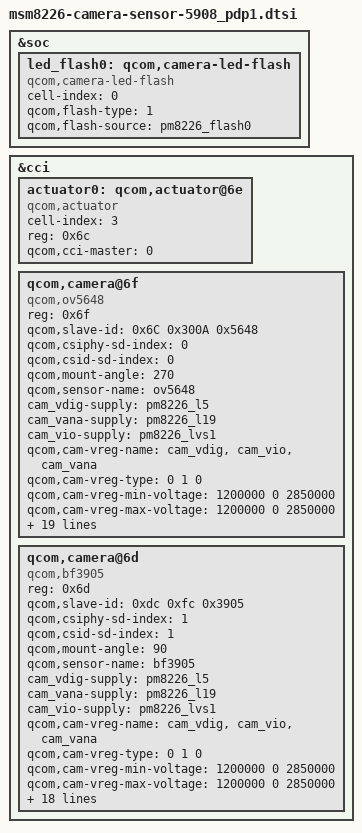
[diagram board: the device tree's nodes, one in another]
/*
 * Copyright (c) 2013, The Linux Foundation. All rights reserved.
 *
 * This program is free software; you can redistribute it and/or modify
 * it under the terms of the GNU General Public License version 2 and
 * only version 2 as published by the Free Software Foundation.
 *
 * This program is distributed in the hope that it will be useful,
 * but WITHOUT ANY WARRANTY; without even the implied warranty of
 * MERCHANTABILITY or FITNESS FOR A PARTICULAR PURPOSE.  See the
 * GNU General Public License for more details.
 */

&soc {

	led_flash0: qcom,camera-led-flash {
		cell-index = <0>;
		compatible = "qcom,camera-led-flash";
		qcom,flash-type = <1>;
		qcom,flash-source = <&pm8226_flash0>;
	};
};

&cci {

	actuator0: qcom,actuator@6e {
		cell-index = <3>;
		reg = <0x6c>;
		compatible = "qcom,actuator";
		qcom,cci-master = <0>;
	};

	qcom,camera@6f {
		compatible = "qcom,ov5648";
		reg = <0x6f>;
		qcom,slave-id = <0x6C 0x300A 0x5648>;
		qcom,csiphy-sd-index = <0>;
		qcom,csid-sd-index = <0>;
		qcom,mount-angle = <270>;
		qcom,sensor-name = "ov5648";
		cam_vdig-supply = <&pm8226_l5>;
		cam_vana-supply = <&pm8226_l19>;
		cam_vio-supply = <&pm8226_lvs1>;
		qcom,cam-vreg-name = "cam_vdig", "cam_vio", "cam_vana";
		qcom,cam-vreg-type = <0 1 0>;
		qcom,cam-vreg-min-voltage = <1200000 0 2850000>;
		qcom,cam-vreg-max-voltage = <1200000 0 2850000>;
		qcom,cam-vreg-op-mode = <200000 0 80000>;
		qcom,gpio-no-mux = <0>;
		gpios = <&msmgpio 26 0>,
			<&msmgpio 37 0>,
			<&msmgpio 12 0>,
			<&msmgpio 13 0>,
			<&msmgpio 109 0>,
			<&msmgpio 35 0>;
		qcom,gpio-reset = <1>;
		qcom,gpio-vio = <2>;
		qcom,gpio-vana = <3>;
		qcom,gpio-vaf = <4>;		
                qcom,gpio-standby = <5>;		
                qcom,gpio-req-tbl-num = <0 1 2 3 4 5>;
		qcom,gpio-req-tbl-flags = <1 0 0 0 0 0>;
		qcom,gpio-req-tbl-label = "CAMIF_MCLK",
			"CAM_RESET1",
			"CAM1_1V8_EN",
			"CAM1_2V8_EN",
			"CAM1_2V7_EN",
			"CAM1_PWDN";
		qcom,csi-lane-assign = <0x4320>;
		qcom,csi-lane-mask = <0x1f>;
		qcom,sensor-position = <0>;
		qcom,sensor-mode = <0>;
		qcom,cci-master = <0>;
	};

	qcom,camera@6d {
		compatible = "qcom,bf3905";
		reg = <0x6d>;
		qcom,slave-id = <0xdc 0xfc 0x3905>;
		qcom,csiphy-sd-index = <1>;
		qcom,csid-sd-index = <1>;
		qcom,mount-angle = <90>;
		qcom,sensor-name = "bf3905";
		cam_vdig-supply = <&pm8226_l5>;
		cam_vana-supply = <&pm8226_l19>;
		cam_vio-supply = <&pm8226_lvs1>;
		qcom,cam-vreg-name = "cam_vdig", "cam_vio", "cam_vana";
		qcom,cam-vreg-type = <0 1 0>;
		qcom,cam-vreg-min-voltage = <1200000 0 2850000>;
		qcom,cam-vreg-max-voltage = <1200000 0 2850000>;
		qcom,cam-vreg-op-mode = <200000 0 80000>;
		qcom,gpio-no-mux = <0>;
		gpios = <&msmgpio 26 0>,
				<&msmgpio 28 0>,
				<&msmgpio 12 0>,
				<&msmgpio 13 0>,
				<&msmgpio 23 0>;
		qcom,gpio-reset = <1>;
		qcom,gpio-req-tbl-num = <0 1 2 3 4>;
		qcom,gpio-req-tbl-flags = <1 0 0 0 0>;
		qcom,gpio-req-tbl-label = "CAMIF_MCLK",
				"CAM_RESET",
				"CAM_VDIG_EN",
				"CAM_VANA_EN",
				"CAM_VIO_EN";
		qcom,gpio-set-tbl-num = <1 1>;
		qcom,gpio-set-tbl-flags = <0 2>;
		qcom,gpio-set-tbl-delay = <1000 4000>;
		qcom,csi-lane-assign = <0x4320>;
		qcom,csi-lane-mask = <0x3>;
		qcom,sensor-position = <1>;
		qcom,sensor-mode = <1>;
		qcom,cci-master = <0>;
		status = "ok";
	};
};
